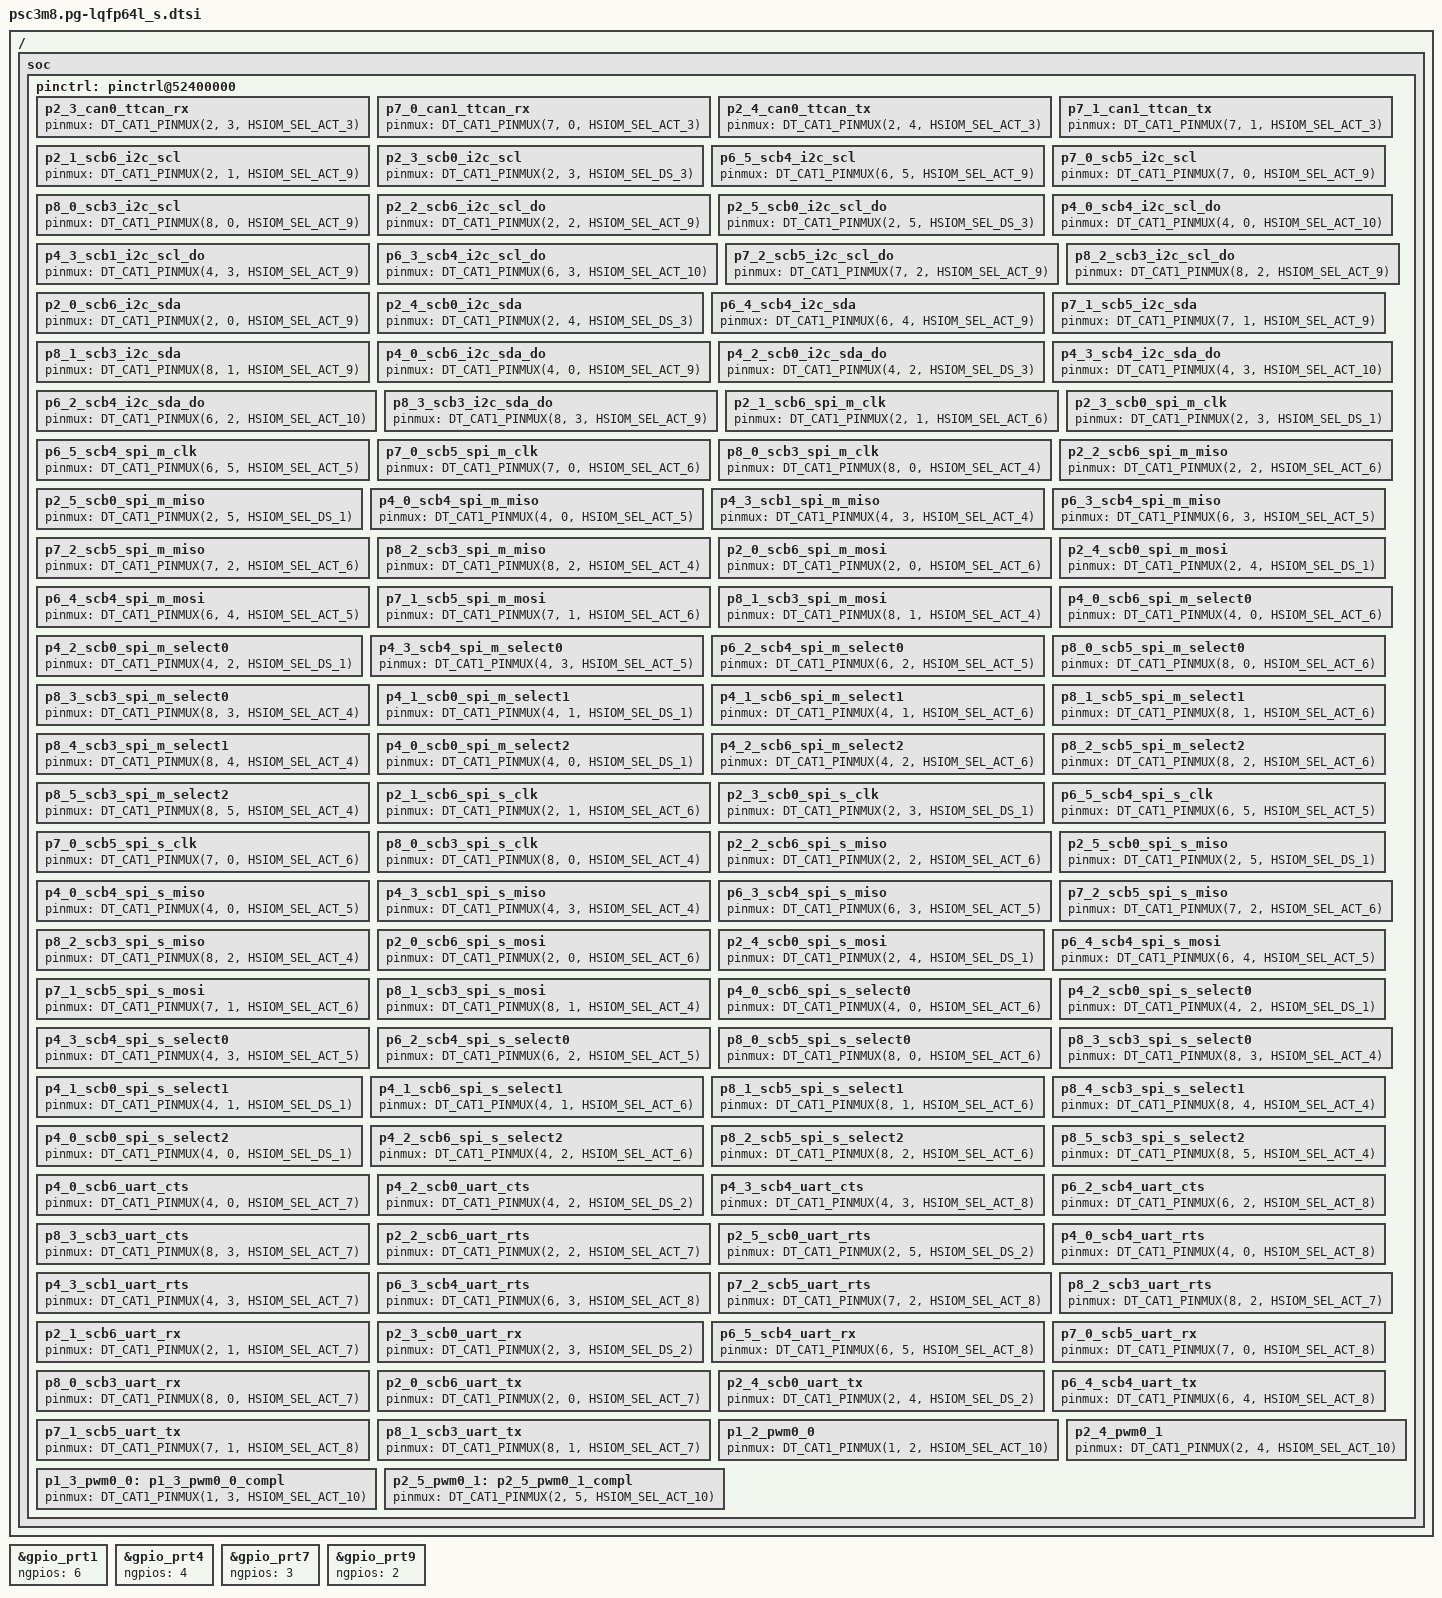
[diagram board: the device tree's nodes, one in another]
/*
 * SPDX-FileCopyrightText: Copyright (c) 2026 Infineon Technologies AG,
 * SPDX-FileCopyrightText: or an affiliate of Infineon Technologies AG. All rights reserved.
 *
 * SPDX-License-Identifier: Apache-2.0
 */

#include <zephyr/dt-bindings/gpio/gpio.h>
#include <zephyr/dt-bindings/pinctrl/ifx_cat1-pinctrl.h>
#include "psc3m8_s.dtsi"

/ {
	soc {
		/delete-node/ gpio@52410000; // gpio_prt0
		/delete-node/ gpio@52410180; // gpio_prt3
		/delete-node/ gpio@52410280; // gpio_prt5

		pinctrl: pinctrl@52400000 {
			/* canfd_ttcan_rx */
			/omit-if-no-ref/ p2_3_can0_ttcan_rx: p2_3_can0_ttcan_rx {
				pinmux = <DT_CAT1_PINMUX(2, 3, HSIOM_SEL_ACT_3)>;
			};

			/omit-if-no-ref/ p7_0_can1_ttcan_rx: p7_0_can1_ttcan_rx {
				pinmux = <DT_CAT1_PINMUX(7, 0, HSIOM_SEL_ACT_3)>;
			};

			/* canfd_ttcan_tx */
			/omit-if-no-ref/ p2_4_can0_ttcan_tx: p2_4_can0_ttcan_tx {
				pinmux = <DT_CAT1_PINMUX(2, 4, HSIOM_SEL_ACT_3)>;
			};

			/omit-if-no-ref/ p7_1_can1_ttcan_tx: p7_1_can1_ttcan_tx {
				pinmux = <DT_CAT1_PINMUX(7, 1, HSIOM_SEL_ACT_3)>;
			};

			/* scb_i2c_scl */
			/omit-if-no-ref/ p2_1_scb6_i2c_scl: p2_1_scb6_i2c_scl {
				pinmux = <DT_CAT1_PINMUX(2, 1, HSIOM_SEL_ACT_9)>;
			};

			/omit-if-no-ref/ p2_3_scb0_i2c_scl: p2_3_scb0_i2c_scl {
				pinmux = <DT_CAT1_PINMUX(2, 3, HSIOM_SEL_DS_3)>;
			};

			/omit-if-no-ref/ p6_5_scb4_i2c_scl: p6_5_scb4_i2c_scl {
				pinmux = <DT_CAT1_PINMUX(6, 5, HSIOM_SEL_ACT_9)>;
			};

			/omit-if-no-ref/ p7_0_scb5_i2c_scl: p7_0_scb5_i2c_scl {
				pinmux = <DT_CAT1_PINMUX(7, 0, HSIOM_SEL_ACT_9)>;
			};

			/omit-if-no-ref/ p8_0_scb3_i2c_scl: p8_0_scb3_i2c_scl {
				pinmux = <DT_CAT1_PINMUX(8, 0, HSIOM_SEL_ACT_9)>;
			};

			/* scb_i2c_scl_do */
			/omit-if-no-ref/ p2_2_scb6_i2c_scl_do: p2_2_scb6_i2c_scl_do {
				pinmux = <DT_CAT1_PINMUX(2, 2, HSIOM_SEL_ACT_9)>;
			};

			/omit-if-no-ref/ p2_5_scb0_i2c_scl_do: p2_5_scb0_i2c_scl_do {
				pinmux = <DT_CAT1_PINMUX(2, 5, HSIOM_SEL_DS_3)>;
			};

			/omit-if-no-ref/ p4_0_scb4_i2c_scl_do: p4_0_scb4_i2c_scl_do {
				pinmux = <DT_CAT1_PINMUX(4, 0, HSIOM_SEL_ACT_10)>;
			};

			/omit-if-no-ref/ p4_3_scb1_i2c_scl_do: p4_3_scb1_i2c_scl_do {
				pinmux = <DT_CAT1_PINMUX(4, 3, HSIOM_SEL_ACT_9)>;
			};

			/omit-if-no-ref/ p6_3_scb4_i2c_scl_do: p6_3_scb4_i2c_scl_do {
				pinmux = <DT_CAT1_PINMUX(6, 3, HSIOM_SEL_ACT_10)>;
			};

			/omit-if-no-ref/ p7_2_scb5_i2c_scl_do: p7_2_scb5_i2c_scl_do {
				pinmux = <DT_CAT1_PINMUX(7, 2, HSIOM_SEL_ACT_9)>;
			};

			/omit-if-no-ref/ p8_2_scb3_i2c_scl_do: p8_2_scb3_i2c_scl_do {
				pinmux = <DT_CAT1_PINMUX(8, 2, HSIOM_SEL_ACT_9)>;
			};

			/* scb_i2c_sda */
			/omit-if-no-ref/ p2_0_scb6_i2c_sda: p2_0_scb6_i2c_sda {
				pinmux = <DT_CAT1_PINMUX(2, 0, HSIOM_SEL_ACT_9)>;
			};

			/omit-if-no-ref/ p2_4_scb0_i2c_sda: p2_4_scb0_i2c_sda {
				pinmux = <DT_CAT1_PINMUX(2, 4, HSIOM_SEL_DS_3)>;
			};

			/omit-if-no-ref/ p6_4_scb4_i2c_sda: p6_4_scb4_i2c_sda {
				pinmux = <DT_CAT1_PINMUX(6, 4, HSIOM_SEL_ACT_9)>;
			};

			/omit-if-no-ref/ p7_1_scb5_i2c_sda: p7_1_scb5_i2c_sda {
				pinmux = <DT_CAT1_PINMUX(7, 1, HSIOM_SEL_ACT_9)>;
			};

			/omit-if-no-ref/ p8_1_scb3_i2c_sda: p8_1_scb3_i2c_sda {
				pinmux = <DT_CAT1_PINMUX(8, 1, HSIOM_SEL_ACT_9)>;
			};

			/* scb_i2c_sda_do */
			/omit-if-no-ref/ p4_0_scb6_i2c_sda_do: p4_0_scb6_i2c_sda_do {
				pinmux = <DT_CAT1_PINMUX(4, 0, HSIOM_SEL_ACT_9)>;
			};

			/omit-if-no-ref/ p4_2_scb0_i2c_sda_do: p4_2_scb0_i2c_sda_do {
				pinmux = <DT_CAT1_PINMUX(4, 2, HSIOM_SEL_DS_3)>;
			};

			/omit-if-no-ref/ p4_3_scb4_i2c_sda_do: p4_3_scb4_i2c_sda_do {
				pinmux = <DT_CAT1_PINMUX(4, 3, HSIOM_SEL_ACT_10)>;
			};

			/omit-if-no-ref/ p6_2_scb4_i2c_sda_do: p6_2_scb4_i2c_sda_do {
				pinmux = <DT_CAT1_PINMUX(6, 2, HSIOM_SEL_ACT_10)>;
			};

			/omit-if-no-ref/ p8_3_scb3_i2c_sda_do: p8_3_scb3_i2c_sda_do {
				pinmux = <DT_CAT1_PINMUX(8, 3, HSIOM_SEL_ACT_9)>;
			};

			/* scb_spi_m_clk */
			/omit-if-no-ref/ p2_1_scb6_spi_m_clk: p2_1_scb6_spi_m_clk {
				pinmux = <DT_CAT1_PINMUX(2, 1, HSIOM_SEL_ACT_6)>;
			};

			/omit-if-no-ref/ p2_3_scb0_spi_m_clk: p2_3_scb0_spi_m_clk {
				pinmux = <DT_CAT1_PINMUX(2, 3, HSIOM_SEL_DS_1)>;
			};

			/omit-if-no-ref/ p6_5_scb4_spi_m_clk: p6_5_scb4_spi_m_clk {
				pinmux = <DT_CAT1_PINMUX(6, 5, HSIOM_SEL_ACT_5)>;
			};

			/omit-if-no-ref/ p7_0_scb5_spi_m_clk: p7_0_scb5_spi_m_clk {
				pinmux = <DT_CAT1_PINMUX(7, 0, HSIOM_SEL_ACT_6)>;
			};

			/omit-if-no-ref/ p8_0_scb3_spi_m_clk: p8_0_scb3_spi_m_clk {
				pinmux = <DT_CAT1_PINMUX(8, 0, HSIOM_SEL_ACT_4)>;
			};

			/* scb_spi_m_miso */
			/omit-if-no-ref/ p2_2_scb6_spi_m_miso: p2_2_scb6_spi_m_miso {
				pinmux = <DT_CAT1_PINMUX(2, 2, HSIOM_SEL_ACT_6)>;
			};

			/omit-if-no-ref/ p2_5_scb0_spi_m_miso: p2_5_scb0_spi_m_miso {
				pinmux = <DT_CAT1_PINMUX(2, 5, HSIOM_SEL_DS_1)>;
			};

			/omit-if-no-ref/ p4_0_scb4_spi_m_miso: p4_0_scb4_spi_m_miso {
				pinmux = <DT_CAT1_PINMUX(4, 0, HSIOM_SEL_ACT_5)>;
			};

			/omit-if-no-ref/ p4_3_scb1_spi_m_miso: p4_3_scb1_spi_m_miso {
				pinmux = <DT_CAT1_PINMUX(4, 3, HSIOM_SEL_ACT_4)>;
			};

			/omit-if-no-ref/ p6_3_scb4_spi_m_miso: p6_3_scb4_spi_m_miso {
				pinmux = <DT_CAT1_PINMUX(6, 3, HSIOM_SEL_ACT_5)>;
			};

			/omit-if-no-ref/ p7_2_scb5_spi_m_miso: p7_2_scb5_spi_m_miso {
				pinmux = <DT_CAT1_PINMUX(7, 2, HSIOM_SEL_ACT_6)>;
			};

			/omit-if-no-ref/ p8_2_scb3_spi_m_miso: p8_2_scb3_spi_m_miso {
				pinmux = <DT_CAT1_PINMUX(8, 2, HSIOM_SEL_ACT_4)>;
			};

			/* scb_spi_m_mosi */
			/omit-if-no-ref/ p2_0_scb6_spi_m_mosi: p2_0_scb6_spi_m_mosi {
				pinmux = <DT_CAT1_PINMUX(2, 0, HSIOM_SEL_ACT_6)>;
			};

			/omit-if-no-ref/ p2_4_scb0_spi_m_mosi: p2_4_scb0_spi_m_mosi {
				pinmux = <DT_CAT1_PINMUX(2, 4, HSIOM_SEL_DS_1)>;
			};

			/omit-if-no-ref/ p6_4_scb4_spi_m_mosi: p6_4_scb4_spi_m_mosi {
				pinmux = <DT_CAT1_PINMUX(6, 4, HSIOM_SEL_ACT_5)>;
			};

			/omit-if-no-ref/ p7_1_scb5_spi_m_mosi: p7_1_scb5_spi_m_mosi {
				pinmux = <DT_CAT1_PINMUX(7, 1, HSIOM_SEL_ACT_6)>;
			};

			/omit-if-no-ref/ p8_1_scb3_spi_m_mosi: p8_1_scb3_spi_m_mosi {
				pinmux = <DT_CAT1_PINMUX(8, 1, HSIOM_SEL_ACT_4)>;
			};

			/* scb_spi_m_select0 */
			/omit-if-no-ref/ p4_0_scb6_spi_m_select0: p4_0_scb6_spi_m_select0 {
				pinmux = <DT_CAT1_PINMUX(4, 0, HSIOM_SEL_ACT_6)>;
			};

			/omit-if-no-ref/ p4_2_scb0_spi_m_select0: p4_2_scb0_spi_m_select0 {
				pinmux = <DT_CAT1_PINMUX(4, 2, HSIOM_SEL_DS_1)>;
			};

			/omit-if-no-ref/ p4_3_scb4_spi_m_select0: p4_3_scb4_spi_m_select0 {
				pinmux = <DT_CAT1_PINMUX(4, 3, HSIOM_SEL_ACT_5)>;
			};

			/omit-if-no-ref/ p6_2_scb4_spi_m_select0: p6_2_scb4_spi_m_select0 {
				pinmux = <DT_CAT1_PINMUX(6, 2, HSIOM_SEL_ACT_5)>;
			};

			/omit-if-no-ref/ p8_0_scb5_spi_m_select0: p8_0_scb5_spi_m_select0 {
				pinmux = <DT_CAT1_PINMUX(8, 0, HSIOM_SEL_ACT_6)>;
			};

			/omit-if-no-ref/ p8_3_scb3_spi_m_select0: p8_3_scb3_spi_m_select0 {
				pinmux = <DT_CAT1_PINMUX(8, 3, HSIOM_SEL_ACT_4)>;
			};

			/* scb_spi_m_select1 */
			/omit-if-no-ref/ p4_1_scb0_spi_m_select1: p4_1_scb0_spi_m_select1 {
				pinmux = <DT_CAT1_PINMUX(4, 1, HSIOM_SEL_DS_1)>;
			};

			/omit-if-no-ref/ p4_1_scb6_spi_m_select1: p4_1_scb6_spi_m_select1 {
				pinmux = <DT_CAT1_PINMUX(4, 1, HSIOM_SEL_ACT_6)>;
			};

			/omit-if-no-ref/ p8_1_scb5_spi_m_select1: p8_1_scb5_spi_m_select1 {
				pinmux = <DT_CAT1_PINMUX(8, 1, HSIOM_SEL_ACT_6)>;
			};

			/omit-if-no-ref/ p8_4_scb3_spi_m_select1: p8_4_scb3_spi_m_select1 {
				pinmux = <DT_CAT1_PINMUX(8, 4, HSIOM_SEL_ACT_4)>;
			};

			/* scb_spi_m_select2 */
			/omit-if-no-ref/ p4_0_scb0_spi_m_select2: p4_0_scb0_spi_m_select2 {
				pinmux = <DT_CAT1_PINMUX(4, 0, HSIOM_SEL_DS_1)>;
			};

			/omit-if-no-ref/ p4_2_scb6_spi_m_select2: p4_2_scb6_spi_m_select2 {
				pinmux = <DT_CAT1_PINMUX(4, 2, HSIOM_SEL_ACT_6)>;
			};

			/omit-if-no-ref/ p8_2_scb5_spi_m_select2: p8_2_scb5_spi_m_select2 {
				pinmux = <DT_CAT1_PINMUX(8, 2, HSIOM_SEL_ACT_6)>;
			};

			/omit-if-no-ref/ p8_5_scb3_spi_m_select2: p8_5_scb3_spi_m_select2 {
				pinmux = <DT_CAT1_PINMUX(8, 5, HSIOM_SEL_ACT_4)>;
			};

			/* scb_spi_s_clk */
			/omit-if-no-ref/ p2_1_scb6_spi_s_clk: p2_1_scb6_spi_s_clk {
				pinmux = <DT_CAT1_PINMUX(2, 1, HSIOM_SEL_ACT_6)>;
			};

			/omit-if-no-ref/ p2_3_scb0_spi_s_clk: p2_3_scb0_spi_s_clk {
				pinmux = <DT_CAT1_PINMUX(2, 3, HSIOM_SEL_DS_1)>;
			};

			/omit-if-no-ref/ p6_5_scb4_spi_s_clk: p6_5_scb4_spi_s_clk {
				pinmux = <DT_CAT1_PINMUX(6, 5, HSIOM_SEL_ACT_5)>;
			};

			/omit-if-no-ref/ p7_0_scb5_spi_s_clk: p7_0_scb5_spi_s_clk {
				pinmux = <DT_CAT1_PINMUX(7, 0, HSIOM_SEL_ACT_6)>;
			};

			/omit-if-no-ref/ p8_0_scb3_spi_s_clk: p8_0_scb3_spi_s_clk {
				pinmux = <DT_CAT1_PINMUX(8, 0, HSIOM_SEL_ACT_4)>;
			};

			/* scb_spi_s_miso */
			/omit-if-no-ref/ p2_2_scb6_spi_s_miso: p2_2_scb6_spi_s_miso {
				pinmux = <DT_CAT1_PINMUX(2, 2, HSIOM_SEL_ACT_6)>;
			};

			/omit-if-no-ref/ p2_5_scb0_spi_s_miso: p2_5_scb0_spi_s_miso {
				pinmux = <DT_CAT1_PINMUX(2, 5, HSIOM_SEL_DS_1)>;
			};

			/omit-if-no-ref/ p4_0_scb4_spi_s_miso: p4_0_scb4_spi_s_miso {
				pinmux = <DT_CAT1_PINMUX(4, 0, HSIOM_SEL_ACT_5)>;
			};

			/omit-if-no-ref/ p4_3_scb1_spi_s_miso: p4_3_scb1_spi_s_miso {
				pinmux = <DT_CAT1_PINMUX(4, 3, HSIOM_SEL_ACT_4)>;
			};

			/omit-if-no-ref/ p6_3_scb4_spi_s_miso: p6_3_scb4_spi_s_miso {
				pinmux = <DT_CAT1_PINMUX(6, 3, HSIOM_SEL_ACT_5)>;
			};

			/omit-if-no-ref/ p7_2_scb5_spi_s_miso: p7_2_scb5_spi_s_miso {
				pinmux = <DT_CAT1_PINMUX(7, 2, HSIOM_SEL_ACT_6)>;
			};

			/omit-if-no-ref/ p8_2_scb3_spi_s_miso: p8_2_scb3_spi_s_miso {
				pinmux = <DT_CAT1_PINMUX(8, 2, HSIOM_SEL_ACT_4)>;
			};

			/* scb_spi_s_mosi */
			/omit-if-no-ref/ p2_0_scb6_spi_s_mosi: p2_0_scb6_spi_s_mosi {
				pinmux = <DT_CAT1_PINMUX(2, 0, HSIOM_SEL_ACT_6)>;
			};

			/omit-if-no-ref/ p2_4_scb0_spi_s_mosi: p2_4_scb0_spi_s_mosi {
				pinmux = <DT_CAT1_PINMUX(2, 4, HSIOM_SEL_DS_1)>;
			};

			/omit-if-no-ref/ p6_4_scb4_spi_s_mosi: p6_4_scb4_spi_s_mosi {
				pinmux = <DT_CAT1_PINMUX(6, 4, HSIOM_SEL_ACT_5)>;
			};

			/omit-if-no-ref/ p7_1_scb5_spi_s_mosi: p7_1_scb5_spi_s_mosi {
				pinmux = <DT_CAT1_PINMUX(7, 1, HSIOM_SEL_ACT_6)>;
			};

			/omit-if-no-ref/ p8_1_scb3_spi_s_mosi: p8_1_scb3_spi_s_mosi {
				pinmux = <DT_CAT1_PINMUX(8, 1, HSIOM_SEL_ACT_4)>;
			};

			/* scb_spi_s_select0 */
			/omit-if-no-ref/ p4_0_scb6_spi_s_select0: p4_0_scb6_spi_s_select0 {
				pinmux = <DT_CAT1_PINMUX(4, 0, HSIOM_SEL_ACT_6)>;
			};

			/omit-if-no-ref/ p4_2_scb0_spi_s_select0: p4_2_scb0_spi_s_select0 {
				pinmux = <DT_CAT1_PINMUX(4, 2, HSIOM_SEL_DS_1)>;
			};

			/omit-if-no-ref/ p4_3_scb4_spi_s_select0: p4_3_scb4_spi_s_select0 {
				pinmux = <DT_CAT1_PINMUX(4, 3, HSIOM_SEL_ACT_5)>;
			};

			/omit-if-no-ref/ p6_2_scb4_spi_s_select0: p6_2_scb4_spi_s_select0 {
				pinmux = <DT_CAT1_PINMUX(6, 2, HSIOM_SEL_ACT_5)>;
			};

			/omit-if-no-ref/ p8_0_scb5_spi_s_select0: p8_0_scb5_spi_s_select0 {
				pinmux = <DT_CAT1_PINMUX(8, 0, HSIOM_SEL_ACT_6)>;
			};

			/omit-if-no-ref/ p8_3_scb3_spi_s_select0: p8_3_scb3_spi_s_select0 {
				pinmux = <DT_CAT1_PINMUX(8, 3, HSIOM_SEL_ACT_4)>;
			};

			/* scb_spi_s_select1 */
			/omit-if-no-ref/ p4_1_scb0_spi_s_select1: p4_1_scb0_spi_s_select1 {
				pinmux = <DT_CAT1_PINMUX(4, 1, HSIOM_SEL_DS_1)>;
			};

			/omit-if-no-ref/ p4_1_scb6_spi_s_select1: p4_1_scb6_spi_s_select1 {
				pinmux = <DT_CAT1_PINMUX(4, 1, HSIOM_SEL_ACT_6)>;
			};

			/omit-if-no-ref/ p8_1_scb5_spi_s_select1: p8_1_scb5_spi_s_select1 {
				pinmux = <DT_CAT1_PINMUX(8, 1, HSIOM_SEL_ACT_6)>;
			};

			/omit-if-no-ref/ p8_4_scb3_spi_s_select1: p8_4_scb3_spi_s_select1 {
				pinmux = <DT_CAT1_PINMUX(8, 4, HSIOM_SEL_ACT_4)>;
			};

			/* scb_spi_s_select2 */
			/omit-if-no-ref/ p4_0_scb0_spi_s_select2: p4_0_scb0_spi_s_select2 {
				pinmux = <DT_CAT1_PINMUX(4, 0, HSIOM_SEL_DS_1)>;
			};

			/omit-if-no-ref/ p4_2_scb6_spi_s_select2: p4_2_scb6_spi_s_select2 {
				pinmux = <DT_CAT1_PINMUX(4, 2, HSIOM_SEL_ACT_6)>;
			};

			/omit-if-no-ref/ p8_2_scb5_spi_s_select2: p8_2_scb5_spi_s_select2 {
				pinmux = <DT_CAT1_PINMUX(8, 2, HSIOM_SEL_ACT_6)>;
			};

			/omit-if-no-ref/ p8_5_scb3_spi_s_select2: p8_5_scb3_spi_s_select2 {
				pinmux = <DT_CAT1_PINMUX(8, 5, HSIOM_SEL_ACT_4)>;
			};

			/* scb_uart_cts */
			/omit-if-no-ref/ p4_0_scb6_uart_cts: p4_0_scb6_uart_cts {
				pinmux = <DT_CAT1_PINMUX(4, 0, HSIOM_SEL_ACT_7)>;
			};

			/omit-if-no-ref/ p4_2_scb0_uart_cts: p4_2_scb0_uart_cts {
				pinmux = <DT_CAT1_PINMUX(4, 2, HSIOM_SEL_DS_2)>;
			};

			/omit-if-no-ref/ p4_3_scb4_uart_cts: p4_3_scb4_uart_cts {
				pinmux = <DT_CAT1_PINMUX(4, 3, HSIOM_SEL_ACT_8)>;
			};

			/omit-if-no-ref/ p6_2_scb4_uart_cts: p6_2_scb4_uart_cts {
				pinmux = <DT_CAT1_PINMUX(6, 2, HSIOM_SEL_ACT_8)>;
			};

			/omit-if-no-ref/ p8_3_scb3_uart_cts: p8_3_scb3_uart_cts {
				pinmux = <DT_CAT1_PINMUX(8, 3, HSIOM_SEL_ACT_7)>;
			};

			/* scb_uart_rts */
			/omit-if-no-ref/ p2_2_scb6_uart_rts: p2_2_scb6_uart_rts {
				pinmux = <DT_CAT1_PINMUX(2, 2, HSIOM_SEL_ACT_7)>;
			};

			/omit-if-no-ref/ p2_5_scb0_uart_rts: p2_5_scb0_uart_rts {
				pinmux = <DT_CAT1_PINMUX(2, 5, HSIOM_SEL_DS_2)>;
			};

			/omit-if-no-ref/ p4_0_scb4_uart_rts: p4_0_scb4_uart_rts {
				pinmux = <DT_CAT1_PINMUX(4, 0, HSIOM_SEL_ACT_8)>;
			};

			/omit-if-no-ref/ p4_3_scb1_uart_rts: p4_3_scb1_uart_rts {
				pinmux = <DT_CAT1_PINMUX(4, 3, HSIOM_SEL_ACT_7)>;
			};

			/omit-if-no-ref/ p6_3_scb4_uart_rts: p6_3_scb4_uart_rts {
				pinmux = <DT_CAT1_PINMUX(6, 3, HSIOM_SEL_ACT_8)>;
			};

			/omit-if-no-ref/ p7_2_scb5_uart_rts: p7_2_scb5_uart_rts {
				pinmux = <DT_CAT1_PINMUX(7, 2, HSIOM_SEL_ACT_8)>;
			};

			/omit-if-no-ref/ p8_2_scb3_uart_rts: p8_2_scb3_uart_rts {
				pinmux = <DT_CAT1_PINMUX(8, 2, HSIOM_SEL_ACT_7)>;
			};

			/* scb_uart_rx */
			/omit-if-no-ref/ p2_1_scb6_uart_rx: p2_1_scb6_uart_rx {
				pinmux = <DT_CAT1_PINMUX(2, 1, HSIOM_SEL_ACT_7)>;
			};

			/omit-if-no-ref/ p2_3_scb0_uart_rx: p2_3_scb0_uart_rx {
				pinmux = <DT_CAT1_PINMUX(2, 3, HSIOM_SEL_DS_2)>;
			};

			/omit-if-no-ref/ p6_5_scb4_uart_rx: p6_5_scb4_uart_rx {
				pinmux = <DT_CAT1_PINMUX(6, 5, HSIOM_SEL_ACT_8)>;
			};

			/omit-if-no-ref/ p7_0_scb5_uart_rx: p7_0_scb5_uart_rx {
				pinmux = <DT_CAT1_PINMUX(7, 0, HSIOM_SEL_ACT_8)>;
			};

			/omit-if-no-ref/ p8_0_scb3_uart_rx: p8_0_scb3_uart_rx {
				pinmux = <DT_CAT1_PINMUX(8, 0, HSIOM_SEL_ACT_7)>;
			};

			/* scb_uart_tx */
			/omit-if-no-ref/ p2_0_scb6_uart_tx: p2_0_scb6_uart_tx {
				pinmux = <DT_CAT1_PINMUX(2, 0, HSIOM_SEL_ACT_7)>;
			};

			/omit-if-no-ref/ p2_4_scb0_uart_tx: p2_4_scb0_uart_tx {
				pinmux = <DT_CAT1_PINMUX(2, 4, HSIOM_SEL_DS_2)>;
			};

			/omit-if-no-ref/ p6_4_scb4_uart_tx: p6_4_scb4_uart_tx {
				pinmux = <DT_CAT1_PINMUX(6, 4, HSIOM_SEL_ACT_8)>;
			};

			/omit-if-no-ref/ p7_1_scb5_uart_tx: p7_1_scb5_uart_tx {
				pinmux = <DT_CAT1_PINMUX(7, 1, HSIOM_SEL_ACT_8)>;
			};

			/omit-if-no-ref/ p8_1_scb3_uart_tx: p8_1_scb3_uart_tx {
				pinmux = <DT_CAT1_PINMUX(8, 1, HSIOM_SEL_ACT_7)>;
			};

			/* PWM tcpwm_line*/
			/omit-if-no-ref/ p1_2_pwm0_0: p1_2_pwm0_0 {
				pinmux = <DT_CAT1_PINMUX(1, 2, HSIOM_SEL_ACT_10)>;
			};

			/omit-if-no-ref/ p2_4_pwm0_1: p2_4_pwm0_1 {
				pinmux = <DT_CAT1_PINMUX(2, 4, HSIOM_SEL_ACT_10)>;
			};

			/* PWM tcpwm_line_compl*/
			/omit-if-no-ref/ p1_3_pwm0_0: p1_3_pwm0_0_compl {
				pinmux = <DT_CAT1_PINMUX(1, 3, HSIOM_SEL_ACT_10)>;
			};

			/omit-if-no-ref/ p2_5_pwm0_1: p2_5_pwm0_1_compl {
				pinmux = <DT_CAT1_PINMUX(2, 5, HSIOM_SEL_ACT_10)>;
			};
		};
	};
};

&gpio_prt1 {
	ngpios = <6>;
};

&gpio_prt4 {
	ngpios = <4>;
};

&gpio_prt7 {
	ngpios = <3>;
};

&gpio_prt9 {
	ngpios = <2>;
};
